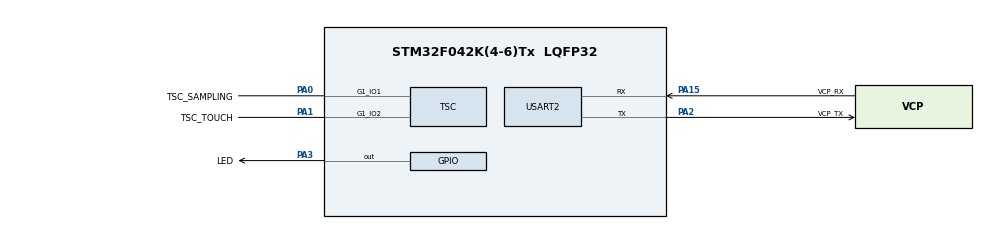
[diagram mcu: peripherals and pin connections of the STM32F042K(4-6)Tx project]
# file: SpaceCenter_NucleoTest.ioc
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Mcu.Family=STM32F0
Mcu.Name=STM32F042K(4-6)Tx
Mcu.Package=LQFP32
PA0.GPIO_Label=TSC_SAMPLING
PA0.Mode=G1_IO1-Sampling
PA0.Signal=TSC_G1_IO1
PA1.GPIO_Label=TSC_TOUCH
PA1.Mode=G1_IO2-Channel
PA1.Signal=TSC_G1_IO2
PA13.GPIO_Label=SWDIO
PA13.Mode=Serial_Wire
PA13.Signal=SYS_SWDIO
PA14.GPIO_Label=SWCLK
PA14.Mode=Serial_Wire
PA14.Signal=SYS_SWCLK
PA15.GPIO_Label=VCP_RX
PA15.Mode=Asynchronous
PA15.Signal=USART2_RX
PA2.GPIO_Label=VCP_TX
PA2.Mode=Asynchronous
PA2.Signal=USART2_TX
PA3.GPIO_Label=LED
PA3.Signal=GPIO_Output
PF0-OSC_IN.GPIO_Label=MCO
PF0-OSC_IN.Mode=HSE-External-Clock-Source
PF0-OSC_IN.Signal=RCC_OSC_IN
ProjectManager.HeapSize=0x200
ProjectManager.StackSize=0x400
ProjectManager.TargetToolchain=STM32CubeIDE
TOUCHSENSING.IO_TOUCHKEY1-TouchSensing_Enabled=G1_IO2
TOUCHSENSING.IO_TOUCHKEY_B1=G1_IO2
TOUCHSENSING.TSLPRM_SENSORS_DATAS=TSLPRM_TOTAL_TOUCHKEYS_B 1 1 
TOUCHSENSING.TSLPRM_TOTAL_TOUCHKEYS=0
TOUCHSENSING.TSLPRM_TOTAL_TOUCHKEYS_B=1
TSC.ChannelIOs-G1_IO2-Channel=TSC_GROUP1_IO2
TSC.SamplingIOs-G1_IO1-Sampling=TSC_GROUP1_IO1
USART2.VirtualMode-Asynchronous=VM_ASYNC
VP_TOUCHSENSING_VS_TOUCHSENSING.Mode=TouchSensing_Enabled
board=NUCLEO-F042K6

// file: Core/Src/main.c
/* USER CODE BEGIN Header */
/**
  ******************************************************************************
  * @file           : main.c
  * @brief          : Main program body
  ******************************************************************************
  * @attention
  *
  * <h2><center>&copy; Copyright (c) 2020 STMicroelectronics.
  * All rights reserved.</center></h2>
  *
  * This software component is licensed by ST under BSD 3-Clause license,
  * the "License"; You may not use this file except in compliance with the
  * License. You may obtain a copy of the License at:
  *                        opensource.org/licenses/BSD-3-Clause
  *
  ******************************************************************************
  */
/* USER CODE END Header */
#include "main.h"
#include "touchsensing.h"

TSC_HandleTypeDef htsc;

UART_HandleTypeDef huart2;

void SystemClock_Config(void);
static void MX_GPIO_Init(void);
static void MX_USART2_UART_Init(void);
static void MX_TSC_Init(void);

int main(void)
{

  /* MCU Configuration--------------------------------------------------------*/

  /* Reset of all peripherals, Initializes the Flash interface and the Systick. */
  HAL_Init();

  /* Configure the system clock */
  SystemClock_Config();

  /* Initialize all configured peripherals */
  MX_GPIO_Init();
  MX_USART2_UART_Init();
  MX_TSC_Init();
  MX_TOUCHSENSING_Init();
  /* USER CODE BEGIN 2 */
  tsl_user_Init();
  /* USER CODE END 2 */

  /* Infinite loop */
  /* USER CODE BEGIN WHILE */
  HAL_GPIO_WritePin(LED_GPIO_Port, LED_Pin, GPIO_PIN_RESET);

  while (1)
  {
    /* USER CODE END WHILE */

    /* USER CODE BEGIN 3 */
	tsl_user_Exec();
	if (MyTKeysB[0].p_Data->StateId == TSL_STATEID_DETECT) {
	  HAL_GPIO_WritePin(LED_GPIO_Port, LED_Pin, GPIO_PIN_SET);
	} else {
	  HAL_GPIO_WritePin(LED_GPIO_Port, LED_Pin, GPIO_PIN_RESET);
	}
	HAL_Delay(50);
  }
  /* USER CODE END 3 */
}

void SystemClock_Config(void)
{
  RCC_OscInitTypeDef RCC_OscInitStruct = {0};
  RCC_ClkInitTypeDef RCC_ClkInitStruct = {0};

  /** Initializes the RCC Oscillators according to the specified parameters
  * in the RCC_OscInitTypeDef structure.
  */
  RCC_OscInitStruct.OscillatorType = RCC_OSCILLATORTYPE_HSI;
  RCC_OscInitStruct.HSIState = RCC_HSI_ON;
  RCC_OscInitStruct.HSICalibrationValue = RCC_HSICALIBRATION_DEFAULT;
  RCC_OscInitStruct.PLL.PLLState = RCC_PLL_NONE;
  if (HAL_RCC_OscConfig(&RCC_OscInitStruct) != HAL_OK)
  {
    Error_Handler();
  }
  /** Initializes the CPU, AHB and APB buses clocks
  */
  RCC_ClkInitStruct.ClockType = RCC_CLOCKTYPE_HCLK|RCC_CLOCKTYPE_SYSCLK
                              |RCC_CLOCKTYPE_PCLK1;
  RCC_ClkInitStruct.SYSCLKSource = RCC_SYSCLKSOURCE_HSI;
  RCC_ClkInitStruct.AHBCLKDivider = RCC_SYSCLK_DIV1;
  RCC_ClkInitStruct.APB1CLKDivider = RCC_HCLK_DIV1;

  if (HAL_RCC_ClockConfig(&RCC_ClkInitStruct, FLASH_LATENCY_0) != HAL_OK)
  {
    Error_Handler();
  }
}

static void MX_TSC_Init(void)
{

  /** Configure the TSC peripheral
  */
  htsc.Instance = TSC;
  htsc.Init.CTPulseHighLength = TSC_CTPH_2CYCLES;
  htsc.Init.CTPulseLowLength = TSC_CTPL_2CYCLES;
  htsc.Init.SpreadSpectrum = DISABLE;
  htsc.Init.SpreadSpectrumDeviation = 1;
  htsc.Init.SpreadSpectrumPrescaler = TSC_SS_PRESC_DIV1;
  htsc.Init.PulseGeneratorPrescaler = TSC_PG_PRESC_DIV4;
  htsc.Init.MaxCountValue = TSC_MCV_8191;
  htsc.Init.IODefaultMode = TSC_IODEF_OUT_PP_LOW;
  htsc.Init.SynchroPinPolarity = TSC_SYNC_POLARITY_FALLING;
  htsc.Init.AcquisitionMode = TSC_ACQ_MODE_NORMAL;
  htsc.Init.MaxCountInterrupt = DISABLE;
  htsc.Init.ChannelIOs = TSC_GROUP1_IO2;
  htsc.Init.ShieldIOs = 0;
  htsc.Init.SamplingIOs = TSC_GROUP1_IO1;
  if (HAL_TSC_Init(&htsc) != HAL_OK)
  {
    Error_Handler();
  }

}

static void MX_USART2_UART_Init(void)
{

  huart2.Instance = USART2;
  huart2.Init.BaudRate = 38400;
  huart2.Init.WordLength = UART_WORDLENGTH_8B;
  huart2.Init.StopBits = UART_STOPBITS_1;
  huart2.Init.Parity = UART_PARITY_NONE;
  huart2.Init.Mode = UART_MODE_TX_RX;
  huart2.Init.HwFlowCtl = UART_HWCONTROL_NONE;
  huart2.Init.OverSampling = UART_OVERSAMPLING_16;
  huart2.Init.OneBitSampling = UART_ONE_BIT_SAMPLE_DISABLE;
  huart2.AdvancedInit.AdvFeatureInit = UART_ADVFEATURE_NO_INIT;
  if (HAL_UART_Init(&huart2) != HAL_OK)
  {
    Error_Handler();
  }

}

static void MX_GPIO_Init(void)
{
  GPIO_InitTypeDef GPIO_InitStruct = {0};

  /* GPIO Ports Clock Enable */
  __HAL_RCC_GPIOF_CLK_ENABLE();
  __HAL_RCC_GPIOA_CLK_ENABLE();

  /*Configure GPIO pin Output Level */
  HAL_GPIO_WritePin(LED_GPIO_Port, LED_Pin, GPIO_PIN_RESET);

  /*Configure GPIO pin : LED_Pin */
  GPIO_InitStruct.Pin = LED_Pin;
  GPIO_InitStruct.Mode = GPIO_MODE_OUTPUT_PP;
  GPIO_InitStruct.Pull = GPIO_NOPULL;
  GPIO_InitStruct.Speed = GPIO_SPEED_FREQ_LOW;
  HAL_GPIO_Init(LED_GPIO_Port, &GPIO_InitStruct);

}

void Error_Handler(void)
{
}

/************************ (C) COPYRIGHT STMicroelectronics *****END OF FILE****/
